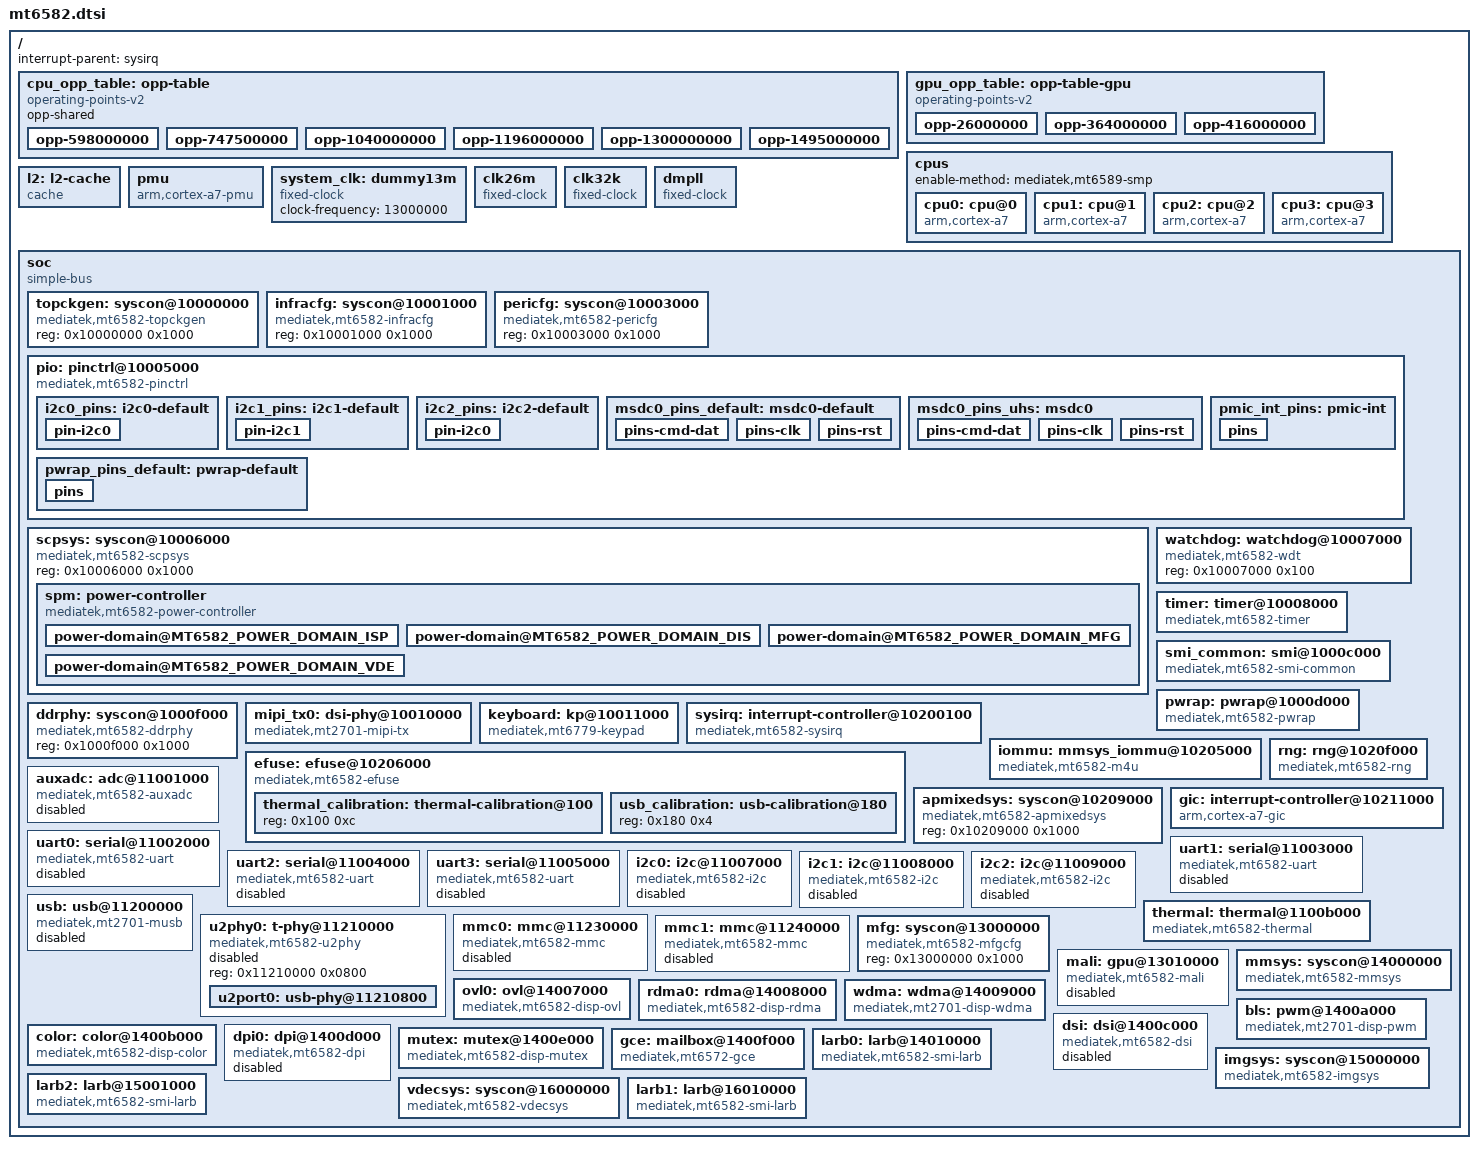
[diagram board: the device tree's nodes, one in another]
// SPDX-License-Identifier: GPL-2.0+
/*
 * Copyright (c) 2021 Maxim Kutnij <gtk3@inbox.ru>
 * Copiright (c) 2026 Burst_Caster <swer15l23@gmail.com>
 */

#include <dt-bindings/interrupt-controller/irq.h>
#include <dt-bindings/interrupt-controller/arm-gic.h>
#include <dt-bindings/clock/mediatek,mt6582-clk.h>
#include <dt-bindings/reset/mediatek,mt6582-resets.h>
#include <dt-bindings/pinctrl/mt6582-pinfunc.h>
#include <dt-bindings/phy/phy.h>
#include <dt-bindings/gpio/gpio.h>
#include <dt-bindings/power/mediatek,mt6582-power.h>
#include <dt-bindings/thermal/thermal.h>
#include <dt-bindings/memory/mediatek,mt6582-larb-port.h>
#include <dt-bindings/gce/mediatek,mt6582-gce.h>

/ {
	#address-cells = <1>;
	#size-cells = <1>;
	interrupt-parent = <&sysirq>;

	cpu_opp_table: opp-table {
		compatible = "operating-points-v2";
		opp-shared;

		
		opp-598000000 {
			opp-hz = /bits/ 64 <598000000>;
			opp-microvolt = <1150000>;
		};

		opp-747500000 {
			opp-hz = /bits/ 64 <747500000>;
			opp-microvolt = <1150000>;
		};

		opp-1040000000 {
			opp-hz = /bits/ 64 <1040000000>;
			opp-microvolt = <1150000>;
		};

		opp-1196000000 {
			opp-hz = /bits/ 64 <1196000000>;
			opp-microvolt = <1200000>;
		};

		opp-1300000000 {
			opp-hz = /bits/ 64 <1300000000>;
			opp-microvolt = <1250000>;
		};

		opp-1495000000 {
			opp-hz = /bits/ 64 <1495000000>;
			opp-microvolt = <1250000>;
		};
	};

	/*
	 * Mali-400 MP2 OPP table.
	 */
	gpu_opp_table: opp-table-gpu {
		compatible = "operating-points-v2";

		opp-26000000 {
			opp-hz = /bits/ 64 <26000000>;
			opp-microvolt = <1150000>;
		};

		opp-364000000 {
			opp-hz = /bits/ 64 <364000000>;
			opp-microvolt = <1150000>;
		};

		opp-416000000 {
			opp-hz = /bits/ 64 <416000000>;
			opp-microvolt = <1150000>;
		};
	};

	cpus {
		#size-cells = <0>;
		#address-cells = <1>;
		enable-method = "mediatek,mt6589-smp";

		cpu0: cpu@0 {
			device_type = "cpu";
			compatible = "arm,cortex-a7";
			reg = <0x0>;
			clocks = <&infracfg CLK_INFRA_CPUSEL>,
				 <&apmixedsys CLK_APMIXED_MAINPLL>;
			clock-names = "cpu", "intermediate";
			operating-points-v2 = <&cpu_opp_table>;
			#cooling-cells = <2>;
			clock-frequency = <1300000000>;
			i-cache-size = <32768>;
			i-cache-line-size = <64>;
			i-cache-sets = <512>;
			d-cache-size = <32768>;
			d-cache-line-size = <64>;
			d-cache-sets = <128>;
			next-level-cache = <&l2>;
		};

		cpu1: cpu@1 {
			device_type = "cpu";
			compatible = "arm,cortex-a7";
			reg = <0x1>;
			clocks = <&infracfg CLK_INFRA_CPUSEL>,
				 <&apmixedsys CLK_APMIXED_MAINPLL>;
			clock-names = "cpu", "intermediate";
			operating-points-v2 = <&cpu_opp_table>;
			#cooling-cells = <2>;
			clock-frequency = <1300000000>;
			i-cache-size = <32768>;
			i-cache-line-size = <64>;
			i-cache-sets = <512>;
			d-cache-size = <32768>;
			d-cache-line-size = <64>;
			d-cache-sets = <128>;
			next-level-cache = <&l2>;
		};

		cpu2: cpu@2 {
			device_type = "cpu";
			compatible = "arm,cortex-a7";
			reg = <0x2>;
			clocks = <&infracfg CLK_INFRA_CPUSEL>,
				 <&apmixedsys CLK_APMIXED_MAINPLL>;
			clock-names = "cpu", "intermediate";
			operating-points-v2 = <&cpu_opp_table>;
			#cooling-cells = <2>;
			clock-frequency = <1300000000>;
			i-cache-size = <32768>;
			i-cache-line-size = <64>;
			i-cache-sets = <512>;
			d-cache-size = <32768>;
			d-cache-line-size = <64>;
			d-cache-sets = <128>;
			next-level-cache = <&l2>;
		};

		cpu3: cpu@3 {
			device_type = "cpu";
			compatible = "arm,cortex-a7";
			reg = <0x3>;
			clocks = <&infracfg CLK_INFRA_CPUSEL>,
				 <&apmixedsys CLK_APMIXED_MAINPLL>;
			clock-names = "cpu", "intermediate";
			operating-points-v2 = <&cpu_opp_table>;
			#cooling-cells = <2>;
			clock-frequency = <1300000000>;
			i-cache-size = <32768>;
			i-cache-line-size = <64>;
			i-cache-sets = <512>;
			d-cache-size = <32768>;
			d-cache-line-size = <64>;
			d-cache-sets = <128>;
			next-level-cache = <&l2>;
		};
	};

	l2: l2-cache {
		compatible = "cache";
		cache-level = <2>;
		cache-size = <524288>;
		cache-line-size = <64>;
		cache-sets = <1024>;
		cache-unified;
	};

	pmu {
		compatible = "arm,cortex-a7-pmu";
		interrupts = <GIC_SPI 4 IRQ_TYPE_LEVEL_LOW>,
			     <GIC_SPI 5 IRQ_TYPE_LEVEL_LOW>,
			     <GIC_SPI 6 IRQ_TYPE_LEVEL_LOW>,
			     <GIC_SPI 7 IRQ_TYPE_LEVEL_LOW>;
		interrupt-affinity = <&cpu0>, <&cpu1>, <&cpu2>, <&cpu3>;
	};

	system_clk: dummy13m {
		compatible = "fixed-clock";
		#clock-cells = <0>;
		clock-frequency = <13000000>;
	};

	clk26m: clk26m {
            compatible = "fixed-clock";
            #clock-cells = <0>;
            clock-frequency = <26000000>;
            clock-output-names = "clk26m";
	};

	clk32k: clk32k {
            compatible = "fixed-clock";
            #clock-cells = <0>;
            clock-frequency = <32768>;
            clock-output-names = "clk32k";
        };

	dmpll: dmpll {
            compatible = "fixed-clock";
            #clock-cells = <0>;
            clock-frequency = <533000000>;
            clock-output-names = "dmpll";
        };

	soc {
		#address-cells = <1>;
		#size-cells = <1>;
		compatible = "simple-bus";
		ranges;

		topckgen: syscon@10000000 {
			compatible = "mediatek,mt6582-topckgen",
			     	"syscon";
			reg = <0x10000000 0x1000>;
			#clock-cells = <1>;
		};
 		
		infracfg: syscon@10001000 {
			compatible = "mediatek,mt6582-infracfg",
			     	"syscon";
			reg = <0x10001000 0x1000>;
			#clock-cells = <1>;
			#reset-cells = <1>;
		};
		

		pericfg: syscon@10003000 {
			compatible = "mediatek,mt6582-pericfg",
			      	"syscon";
			reg = <0x10003000 0x1000>;
			#clock-cells = <1>;
			#reset-cells = <1>;
		};
		
		pio: pinctrl@10005000 {
    			compatible = "mediatek,mt6582-pinctrl";
    			reg = <0x10005000 0x1000>,
				  <0x1000b000 0x1000>;
			reg-names = "gpio", "eint";
    			#pinctrl-cells = <1>;
			gpio-ranges = <&pio 0 0 168>; 
			gpio-controller;
			#gpio-cells = <2>;
    			interrupt-controller;
    			#interrupt-cells = <2>;
    			interrupt-parent = <&gic>;
    			interrupts = <GIC_SPI 113 IRQ_TYPE_LEVEL_HIGH>,
					 <GIC_SPI 114 IRQ_TYPE_LEVEL_HIGH>;
		};

		scpsys: syscon@10006000 {
			compatible = "mediatek,mt6582-scpsys", "syscon", "simple-mfd";
			reg = <0x10006000 0x1000>;

			spm: power-controller {
				compatible = "mediatek,mt6582-power-controller";
				#address-cells = <1>;
				#size-cells = <0>;
				#power-domain-cells = <1>;
				
				power-domain@MT6582_POWER_DOMAIN_ISP {
					reg = <MT6582_POWER_DOMAIN_ISP>;
					clocks = <&topckgen CLK_TOP_MM_SEL>;
					clock-names = "mm";
					#power-domain-cells = <0>;
				};

				power-domain@MT6582_POWER_DOMAIN_DIS {
					reg = <MT6582_POWER_DOMAIN_DIS>;
					clocks = <&topckgen CLK_TOP_MM_SEL>;
					clock-names = "mm";
					#power-domain-cells = <0>;
					mediatek,infracfg = <&infracfg>;
				};

				power-domain@MT6582_POWER_DOMAIN_MFG {
					reg = <MT6582_POWER_DOMAIN_MFG>;
					clocks = <&topckgen CLK_TOP_MFG_SEL>;
					clock-names = "mfg";
					#power-domain-cells = <0>;
					mediatek,infracfg = <&infracfg>;
				};

				power-domain@MT6582_POWER_DOMAIN_VDE {
					reg = <MT6582_POWER_DOMAIN_VDE>;
					clocks = <&topckgen CLK_TOP_VDEC_SEL>;
					clock-names = "vde";
					#power-domain-cells = <0>;
					mediatek,infracfg = <&infracfg>;
				};

			};
		};

		watchdog: watchdog@10007000 {
			compatible = "mediatek,mt6582-wdt", "mediatek,mt6582-wdt";
			reg = <0x10007000 0x100>;
		};

		timer: timer@10008000 {
			compatible = "mediatek,mt6582-timer", "mediatek,mt6577-timer";
			reg = <0x10008000 0x80>;
			interrupts = <GIC_SPI 112 IRQ_TYPE_LEVEL_LOW>;
			clocks = <&system_clk>, <&clk32k>;
		};

		smi_common: smi@1000c000 {
			compatible = "mediatek,mt6582-smi-common";
			reg = <0x1000c000 0x1000>, <0x14011000 0x1000>;
			clocks = <&infracfg CLK_INFRA_SMI>,
				<&mmsys CLK_MM_SMI_COMMON>;
			clock-names = "apb", "smi";
			power-domains = <&spm MT6582_POWER_DOMAIN_DIS>;
		};

		pwrap: pwrap@1000d000 {
			compatible =
			     "mediatek,mt6582-pwrap";
			reg = < 0x1000d000  0x1000>;
			reg-names = "pwrap";
			interrupts = <GIC_SPI 115 IRQ_TYPE_LEVEL_HIGH>;
			resets = <&infracfg INFRA_RST0_PMIC_WRAP_RST>;
			reset-names = "pwrap";
			clocks = <&topckgen CLK_TOP_PMICSPI_SEL>,
			 	<&infracfg CLK_INFRA_PMICWRAP>;
			clock-names = "spi", "wrap";
			mediatek,syscon = <&infracfg>;
        		pinctrl-names = "default";
        		pinctrl-0 = <&pwrap_pins_default>;
		};
		/* vencpll */
		ddrphy: syscon@1000f000 {
			compatible = "mediatek,mt6582-ddrphy",
			     	"syscon";
			reg = <0x1000f000 0x1000>;
			#clock-cells = <1>;
		};

		mipi_tx0: dsi-phy@10010000 {
			compatible = "mediatek,mt2701-mipi-tx";
			reg = <0x10010000 0x90>;
			clocks = <&clk26m>;
			clock-output-names = "mipi_tx0_pll";
			#clock-cells = <0>;
			#phy-cells = <0>;
			power-domains = <&spm MT6582_POWER_DOMAIN_DIS>;
		};

		keyboard: kp@10011000 {
			compatible = "mediatek,mt6779-keypad";
			reg = <0x10011000 0x1000>;
			interrupts = <GIC_SPI 116 IRQ_TYPE_EDGE_FALLING>;
			clocks = <&infracfg CLK_INFRA_KP>;
			clock-names = "kpd";
        	};

		sysirq: interrupt-controller@10200100 {
			compatible = "mediatek,mt6582-sysirq", "mediatek,mt6577-sysirq";
			reg = <0x10200100 0x1c>;
			interrupt-parent = <&gic>;
			interrupt-controller;
			#interrupt-cells = <3>;
		};

		iommu: mmsys_iommu@10205000 {
			compatible = "mediatek,mt6582-m4u";
			reg = <0x10205000 0x1000>;
			interrupts = <GIC_SPI 106 IRQ_TYPE_LEVEL_LOW>;
			clocks = <&infracfg CLK_INFRA_M4U>, <&infracfg CLK_INFRA_SMI>;
			clock-names = "bclk", "smi";
			mediatek,larbs = <&larb0 &larb1 &larb2>;
			#iommu-cells = <1>;
			// dma-coherent;
		};

		efuse: efuse@10206000 {
			compatible = "mediatek,mt6582-efuse";
					// "mediatek,efuse";
			reg = <0x10206000 0x1000>;
			clocks = <&infracfg CLK_INFRA_EFUSE>;
			clock-names = "efuse";
			#address-cells = <1>;
			#size-cells = <1>;

			/* thermal calibration — 8 байт по смещению 0x100 */
			thermal_calibration: thermal-calibration@100 {
				reg = <0x100 0xc>;
			};

			usb_calibration: usb-calibration@180 {
				reg = <0x180 0x4>;
			};
		};

		apmixedsys: syscon@10209000 {
			compatible = "mediatek,mt6582-apmixedsys",
			     	"syscon";
			reg = <0x10209000 0x1000>;
			#clock-cells = <1>;
		};

		rng: rng@1020f000 {
			compatible = "mediatek,mt6582-rng",
					"mediatek,mt7623-rng";
			reg = < 0x1020f000  0x1000>;
			clocks = <&infracfg CLK_INFRA_TRNG>;
			clock-names = "rng";
			resets = <&infracfg INFRA_RST1_TRNG_RST>;
		};

		gic: interrupt-controller@10211000 {
			compatible = "arm,cortex-a7-gic";
			#interrupt-cells = <3>;
			interrupt-controller;
			interrupt-parent = <&gic>;
			reg = <0x10211000 0x1000>,
			      <0x10212000 0x2000>,
			      <0x10214000 0x2000>,
			      <0x10216000 0x2000>;
		};

		auxadc: adc@11001000 {
			compatible = "mediatek,mt6582-auxadc", "mediatek,mt2701-auxadc";
			reg = <0x11001000 0x1000>;
			clocks = <&pericfg CLK_PERI_AUXADC>;
			clock-names = "main";
			#io-channel-cells = <1>;
			status = "disabled";
		};

		uart0: serial@11002000 {
			compatible = "mediatek,mt6582-uart", "mediatek,mt6577-uart";
			reg = <0x11002000 0x400>;
			interrupts = <GIC_SPI 51 IRQ_TYPE_LEVEL_LOW>;
			clocks = <&clk26m>, <&clk26m>;
			clock-names = "baud", "bus";
			status = "disabled";
		};

		uart1: serial@11003000 {
			compatible = "mediatek,mt6582-uart", "mediatek,mt6577-uart";
			reg = <0x11003000 0x400>;
			interrupts = <GIC_SPI 52 IRQ_TYPE_LEVEL_LOW>;
			clocks = <&clk26m>, <&clk26m>;
			clock-names = "baud", "bus";
			status = "disabled";
		};

		uart2: serial@11004000 {
			compatible = "mediatek,mt6582-uart", "mediatek,mt6577-uart";
			reg = <0x11004000 0x400>;
			interrupts = <GIC_SPI 53 IRQ_TYPE_LEVEL_LOW>;
			clocks = <&clk26m>, <&clk26m>;
			clock-names = "baud", "bus";
			status = "disabled";
		};

		uart3: serial@11005000 {
			compatible = "mediatek,mt6582-uart", "mediatek,mt6577-uart";
			reg = <0x11005000 0x400>;
			interrupts = <GIC_SPI 54 IRQ_TYPE_LEVEL_LOW>;
			clocks = <&clk26m>, <&clk26m>;
			clock-names = "baud", "bus";
			status = "disabled";
		};

		i2c0: i2c@11007000 {
			compatible = "mediatek,mt6582-i2c";
			reg = <0x11007000 0x70>,
		          <0x11000200 0x80>;
			interrupts = <GIC_SPI 44 IRQ_TYPE_LEVEL_LOW>;
			clock-div = <16>;
			clocks = <&pericfg CLK_PERI_I2C0>, <&pericfg CLK_PERI_AP_DMA>;
			clock-names = "main", "dma";
			#address-cells = <1>;
			#size-cells = <0>;
			status = "disabled";
		};

		i2c1: i2c@11008000 {
			compatible = "mediatek,mt6582-i2c";
			reg = <0x11008000 0x70>,
				  <0x11000280 0x80>;
			interrupts = <GIC_SPI 45 IRQ_TYPE_LEVEL_LOW>;
			clock-div = <16>;
			clocks = <&pericfg CLK_PERI_I2C1>, <&pericfg CLK_PERI_AP_DMA>;
			clock-names = "main", "dma";
			#address-cells = <1>;
			#size-cells = <0>;
			status = "disabled";
		};

		i2c2: i2c@11009000 {
			compatible = "mediatek,mt6582-i2c";
			reg = <0x11009000  0x70>,
				  <0x11000360  0x80>;
			interrupts = <GIC_SPI 46 IRQ_TYPE_LEVEL_LOW>;
			clock-div = <16>;
			clocks = <&pericfg CLK_PERI_I2C2>, <&pericfg CLK_PERI_AP_DMA>;
			clock-names = "main", "dma";
			#address-cells = <1>;
			#size-cells = <0>;
			status = "disabled";
		};

		thermal: thermal@1100b000 {
			#thermal-sensor-cells = <0>;
			compatible = "mediatek,mt6582-thermal",
					"mediatek,mt2701-thermal";
			reg = <0x1100b000 0x1000>;
			interrupts = <GIC_SPI 31 IRQ_TYPE_LEVEL_LOW>;
			clocks = <&pericfg CLK_PERI_THERM>,
				<&pericfg CLK_PERI_AUXADC>;
			clock-names = "therm", "auxadc";
			mediatek,auxadc = <&auxadc>;
			mediatek,apmixedsys = <&apmixedsys>;
			nvmem-cells = <&thermal_calibration>;
			nvmem-cell-names = "calibration-data";
		};

		usb: usb@11200000 {
			compatible = "mediatek,mt2701-musb",
				     "mediatek,mtk-musb";
			reg = <0x11200000 0x1000>;
			#address-cells = <1>;
			#size-cells = <1>;
			interrupts = <GIC_SPI 32 IRQ_TYPE_LEVEL_LOW>;
			interrupt-names = "mc";
			phys = <&u2port0 PHY_TYPE_USB2>;
			dr_mode = "otg";
			clocks = <&pericfg CLK_PERI_USB0>,
				 <&pericfg CLK_PERI_USB0>,
				 <&apmixedsys CLK_APMIXED_UNIV48M>;
			clock-names = "main", "mcu", "univpll";
			
			status = "disabled";
		};

		u2phy0: t-phy@11210000 {
			compatible = "mediatek,mt6582-u2phy";
				//      "mediatek,generic-tphy-v1";
			reg = <0x11210000 0x0800>;
			ranges;
			#address-cells = <1>;
			#size-cells = <1>;
			status = "disabled";
			

			u2port0: usb-phy@11210800 {
				reg = <0x11210800 0x0100>;
				clocks = <&apmixedsys CLK_APMIXED_UNIV48M>;
				clock-names = "ref";
				#phy-cells = <1>;
				phy_type = <PHY_TYPE_USB2>;
				
			};
		};

		mmc0: mmc@11230000 {
			compatible = "mediatek,mt6582-mmc";
				
			reg = < 0x11230000  0x1000>;
			interrupts = <GIC_SPI 39 IRQ_TYPE_LEVEL_LOW>;
			clocks = <&pericfg CLK_PERI_MSDC30_0>,
				<&topckgen CLK_TOP_MSDC30_0_SEL>;
			clock-names = "source", "hclk";
			resets = <&pericfg PERI_MSDC0_SW_RST>;
			reset-names = "hrst";
			status = "disabled";
		};

		mmc1: mmc@11240000 {
			compatible = "mediatek,mt6582-mmc";
				
			reg = < 0x11240000  0x1000>;
			interrupts = <GIC_SPI 40 IRQ_TYPE_LEVEL_LOW>;
			clocks = <&pericfg CLK_PERI_MSDC30_1>,
				<&topckgen CLK_TOP_MSDC30_1_SEL>;
			clock-names = "source", "hclk";
			resets = <&pericfg PERI_MSDC1_SW_RST>;
			reset-names = "hrst";
			status = "disabled";
		};

		mfg: syscon@13000000 {                   
			compatible = "mediatek,mt6582-mfgcfg",
				"syscon", "simple-mfd";
			reg = <0x13000000 0x1000>;
			#clock-cells = <1>;
			#reset-cells = <1>;
		};

		mali: gpu@13010000 {
			compatible = "mediatek,mt6582-mali", "arm,mali-400";
			reg = <0x13010000 0x30000>;
			interrupts = <GIC_SPI 170 IRQ_TYPE_LEVEL_LOW>,
				<GIC_SPI 171 IRQ_TYPE_LEVEL_LOW>,
				<GIC_SPI 172 IRQ_TYPE_LEVEL_LOW>,
				<GIC_SPI 173 IRQ_TYPE_LEVEL_LOW>,
				<GIC_SPI 174 IRQ_TYPE_LEVEL_LOW>,
				<GIC_SPI 175 IRQ_TYPE_LEVEL_LOW>;
			interrupt-names = "gp", "gpmmu", "pp0", "ppmmu0", "pp1",
					"ppmmu1";
			clocks =
				<&mfg CLK_MFG_BG3D>,
				<&mfg CLK_MFG_BG3D>;
			clock-names = "bus", "core";
			power-domains = <&spm MT6582_POWER_DOMAIN_MFG>;
			resets = <&mfg MFG_G3D_RESET>;
			operating-points-v2 = <&gpu_opp_table>;
			// assigned-clocks = <&topckgen CLK_TOP_MFG_SEL>;
			// assigned-clock-parents = <&topckgen CLK_TOP_SYSPLL_D3>;
			status = "disabled";
		};

		mmsys: syscon@14000000 {
			compatible = "mediatek,mt6582-mmsys", "syscon";
			reg = <0x14000000 0x1000>;
			#clock-cells = <1>;
			#reset-cells = <1>;
			mboxes = <&gce 0 CMDQ_THR_PRIO_HIGHEST>,
				 <&gce 1 CMDQ_THR_PRIO_HIGHEST>;
			mediatek,gce-client-reg = <&gce SUBSYS_14XXXXXX 0 0x1000>;
		};

		ovl0: ovl@14007000 {
			compatible = "mediatek,mt6582-disp-ovl";
			reg = <0x14007000 0x1000>;
			interrupts = <GIC_SPI 153 IRQ_TYPE_LEVEL_LOW>;
			clocks = <&mmsys CLK_MM_DISP_OVL>;
			iommus = <&iommu M4U_PORT_DISP_OVL0>;
			power-domains = <&spm MT6582_POWER_DOMAIN_DIS>;
			mediatek,gce-client-reg = <&gce SUBSYS_14XXXXXX 0x7000 0x1000>;
			// resets = <&mmsys MMSYS_DISP_OVL_RST>;
			// reset-names = "mmsys_ovl_rst";
		};

		rdma0: rdma@14008000 {
			compatible = "mediatek,mt6582-disp-rdma";
			reg = <0x14008000 0x1000>;
			interrupts = <GIC_SPI 152 IRQ_TYPE_LEVEL_LOW>;
			clocks = <&mmsys CLK_MM_DISP_RDMA>;
			iommus = <&iommu M4U_PORT_DISP_RDMA0>;
			power-domains = <&spm MT6582_POWER_DOMAIN_DIS>;
			mediatek,gce-client-reg = <&gce SUBSYS_14XXXXXX 0x8000 0x1000>;
		};

		wdma: 	wdma@14009000 {
			compatible = "mediatek,mt2701-disp-wdma",
				"mediatek,mt2701-disp-wdma";
			reg = <0x14009000 0x1000>;
			interrupts = <GIC_SPI 154 IRQ_TYPE_LEVEL_LOW>;
			clocks = <&mmsys CLK_MM_DISP_WDMA>;
			iommus = <&iommu M4U_PORT_DISP_WDMA0>;
			//power-domains = <&spm MT6582_POWER_DOMAIN_DIS>;
		};

		bls: pwm@1400a000 {
			compatible = "mediatek,mt2701-disp-pwm";
			reg = <0x1400a000 0x1000>;
			#pwm-cells = <2>;
			clocks = <&mmsys CLK_MM_MDP_BLS_26M>,
				<&mmsys CLK_MM_DISP_BLS>;
			clock-names = "main", "mm";
			power-domains = <&spm MT6582_POWER_DOMAIN_DIS>;
		};

		color: color@1400b000 {
			compatible = "mediatek,mt6582-disp-color",
				"mediatek,mt2701-disp-color";
			reg = <0x1400b000 0x1000>;
			interrupts = <GIC_SPI 156 IRQ_TYPE_LEVEL_LOW>;
			clocks = <&mmsys CLK_MM_DISP_COLOR>;
			power-domains = <&spm MT6582_POWER_DOMAIN_DIS>;
			mediatek,gce-client-reg = <&gce SUBSYS_14XXXXXX 0xb000 0x1000>;
		};
	
		dsi: dsi@1400c000 {
			compatible = "mediatek,mt6582-dsi";
			reg = <0x1400c000 0x1000>;
			interrupts = <GIC_SPI 157 IRQ_TYPE_LEVEL_LOW>;
			clocks = <&mmsys CLK_MM_DSI_ENGINE>,
				<&mmsys CLK_MM_DSI_DIG>,
				<&mipi_tx0>;
			clock-names = "engine", "digital", "hs";
			phys = <&mipi_tx0>;
			phy-names = "dphy";
			power-domains = <&spm MT6582_POWER_DOMAIN_DIS>;
			status = "disabled";
		};

		dpi0: dpi@1400d000 {
			compatible = "mediatek,mt6582-dpi",
				"mediatek,mt2701-dpi";
			reg = <0x1400d000 0x1000>;
			interrupts = <GIC_SPI 158 IRQ_TYPE_LEVEL_LOW>;
			clocks = <&mmsys CLK_MM_DPI_DIGL>,
				<&mmsys CLK_MM_DPI_ENGINE>,
				<&mipi_tx0>;
			clock-names = "pixel", "engine", "pll";
			power-domains = <&spm MT6582_POWER_DOMAIN_DIS>;
			status = "disabled";
		};

		mutex: mutex@1400e000 {                         
			compatible = "mediatek,mt6582-disp-mutex";
			reg = <0x1400e000 0x1000>;
			interrupts = <GIC_SPI 161 IRQ_TYPE_LEVEL_LOW>;
			clocks = <&mmsys CLK_MM_MUTEX_32K>;
			power-domains = <&spm MT6582_POWER_DOMAIN_DIS>;
			mediatek,gce-client-reg = <&gce SUBSYS_14XXXXXX 0xe000 0x1000>;
			mediatek,gce-events = <CMDQ_EVENT_MUTEX0>;
		};

		gce: mailbox@1400f000 {
			compatible = "mediatek,mt6572-gce";
			reg = <0x1400f000 0x1000>;
			interrupts = <GIC_SPI 159 IRQ_TYPE_LEVEL_LOW>;
			clocks = <&mmsys CLK_MM_CMDQ>, <&mmsys CLK_MM_SMI_CMDQ>;
			clock-names = "gce", "smi";
			#mbox-cells = <2>;
			power-domains = <&spm MT6582_POWER_DOMAIN_DIS>;
		};

		larb0: larb@14010000 {
			compatible = "mediatek,mt6582-smi-larb";
			reg = <0x14010000 0x1000>;
			mediatek,smi = <&smi_common>;
			mediatek,larb-id = <0>;
			clocks = <&mmsys CLK_MM_SMI_COMMON>,
				<&mmsys CLK_MM_SMI_LARB0>;
			clock-names = "apb", "smi";
			power-domains = <&spm MT6582_POWER_DOMAIN_DIS>;
		};

		imgsys: syscon@15000000 {
			compatible = "mediatek,mt6582-imgsys",
				"syscon";
			reg = <0x15000000 0x1000>;
			#clock-cells = <1>;
			power-domains = <&spm MT6582_POWER_DOMAIN_ISP>;
		};

		larb2: larb@15001000 {
			compatible = "mediatek,mt6582-smi-larb";
			reg = <0x15001000 0x1000>;
			mediatek,smi = <&smi_common>;
			mediatek,larb-id = <2>;
			clocks = <&mmsys CLK_MM_SMI_COMMON>,
				<&imgsys CLK_IMG_LARB2_SMI>;
			clock-names = "apb", "smi";
			power-domains = <&spm MT6582_POWER_DOMAIN_ISP>;
		};

		vdecsys: syscon@16000000 {
			compatible = "mediatek,mt6582-vdecsys",
				"mediatek,mt2701-vdecsys",
				"syscon";
			reg = <0x16000000 0x1000>;
			#clock-cells = <1>;
			power-domains = <&spm MT6582_POWER_DOMAIN_VDE>;
		};

		larb1: larb@16010000 {
			compatible = "mediatek,mt6582-smi-larb";
			reg = <0x16010000 0x1000>;
			mediatek,smi = <&smi_common>;
			mediatek,larb-id = <1>;
			clocks = <&mmsys CLK_MM_SMI_COMMON>,
				<&vdecsys CLK_VDEC_LARB>;
			clock-names = "apb", "smi";
			power-domains = <&spm MT6582_POWER_DOMAIN_VDE>;
		};
	};
};

&pio {
	i2c0_pins: i2c0-default {
		pin-i2c0 {
			pinmux = <MT6582_PIN_84_SDA0__FUNC_SDA0>,
				 <MT6582_PIN_85_SCL0__FUNC_SCL0>;
			input-enable;
		};
	};

	i2c1_pins: i2c1-default {
		pin-i2c1 {
			pinmux = <MT6582_PIN_86_SDA1__FUNC_SDA1>,
				 <MT6582_PIN_87_SCL1__FUNC_SCL1>;
			input-enable;
		};
	};

	i2c2_pins: i2c2-default {
		pin-i2c0 {
			pinmux = <MT6582_PIN_88_SDA2__FUNC_SDA2>,
				 <MT6582_PIN_89_SCL2__FUNC_SCL2>;
			input-enable;
		};
	};

	msdc0_pins_default: msdc0-default {
		pins-cmd-dat{
			pinmux = <MT6582_PIN_135_MSDC0_CMD__FUNC_MSDC0_CMD>,
				 <MT6582_PIN_140_MSDC0_DAT0__FUNC_MSDC0_DAT0>,
				 <MT6582_PIN_139_MSDC0_DAT1__FUNC_MSDC0_DAT1>,
				 <MT6582_PIN_138_MSDC0_DAT2__FUNC_MSDC0_DAT2>,
				 <MT6582_PIN_137_MSDC0_DAT3__FUNC_MSDC0_DAT3>,
				 <MT6582_PIN_133_MSDC0_DAT4__FUNC_MSDC0_DAT4>,
				 <MT6582_PIN_132_MSDC0_DAT5__FUNC_MSDC0_DAT5>,
				 <MT6582_PIN_131_MSDC0_DAT6__FUNC_MSDC0_DAT6>,
				 <MT6582_PIN_130_MSDC0_DAT7__FUNC_MSDC0_DAT7>;
			input-enable;
			bias-pull-up = <MTK_PUPD_SET_R1R0_01>;

		};
		pins-clk {
			pinmux = <MT6582_PIN_136_MSDC0_CLK__FUNC_MSDC0_CLK>;
			bias-pull-down = <MTK_PUPD_SET_R1R0_01>;
		};
		pins-rst {
			pinmux = <MT6582_PIN_134_MSDC0_RSTB__FUNC_MSDC0_RSTB>;
			bias-pull-up;
		};
	};
	msdc0_pins_uhs: msdc0 {
		pins-cmd-dat{
			pinmux = <MT6582_PIN_135_MSDC0_CMD__FUNC_MSDC0_CMD>,
				 <MT6582_PIN_140_MSDC0_DAT0__FUNC_MSDC0_DAT0>,
				 <MT6582_PIN_139_MSDC0_DAT1__FUNC_MSDC0_DAT1>,
				 <MT6582_PIN_138_MSDC0_DAT2__FUNC_MSDC0_DAT2>,
				 <MT6582_PIN_137_MSDC0_DAT3__FUNC_MSDC0_DAT3>,
				 <MT6582_PIN_133_MSDC0_DAT4__FUNC_MSDC0_DAT4>,
				 <MT6582_PIN_132_MSDC0_DAT5__FUNC_MSDC0_DAT5>,
				 <MT6582_PIN_131_MSDC0_DAT6__FUNC_MSDC0_DAT6>,
				 <MT6582_PIN_130_MSDC0_DAT7__FUNC_MSDC0_DAT7>;
			input-enable;
			drive-strength = <4>;
			bias-pull-up = <MTK_PUPD_SET_R1R0_10>;
		};
		pins-clk {
			pinmux = <MT6582_PIN_136_MSDC0_CLK__FUNC_MSDC0_CLK>;
			drive-strength = <10>;
			bias-pull-down = <MTK_PUPD_SET_R1R0_10>;
		};
		pins-rst {
			pinmux = <MT6582_PIN_134_MSDC0_RSTB__FUNC_MSDC0_RSTB>;
			bias-pull-up;
		};
	};

	pwrap_pins_default: pwrap-default {
		pins {
			pinmux = <MT6582_PIN_21_PWRAP_SPI0_MI__FUNC_PWRAP_SPIDO>,
			<MT6582_PIN_22_PWRAP_SPI0_MO__FUNC_PWRAP_SPIDI>,
			<MT6582_PIN_23_PWRAP_SPI0_CK__FUNC_PWRAP_SPICK_I>,
			<MT6582_PIN_24_PWRAP_SPI0_CSN__FUNC_PWRAP_SPICS_B_I>;
			input-enable;
			bias-disable;
		};
        
    	};

	pmic_int_pins: pmic-int {
		pins {
			pinmux = <MT6582_PIN_25_PWRAP_INT__FUNC_GPIO25>;
			input-enable;
			bias-pull-down; 
			debounce-interval = <1000>; 
		};
    	};
	

};
